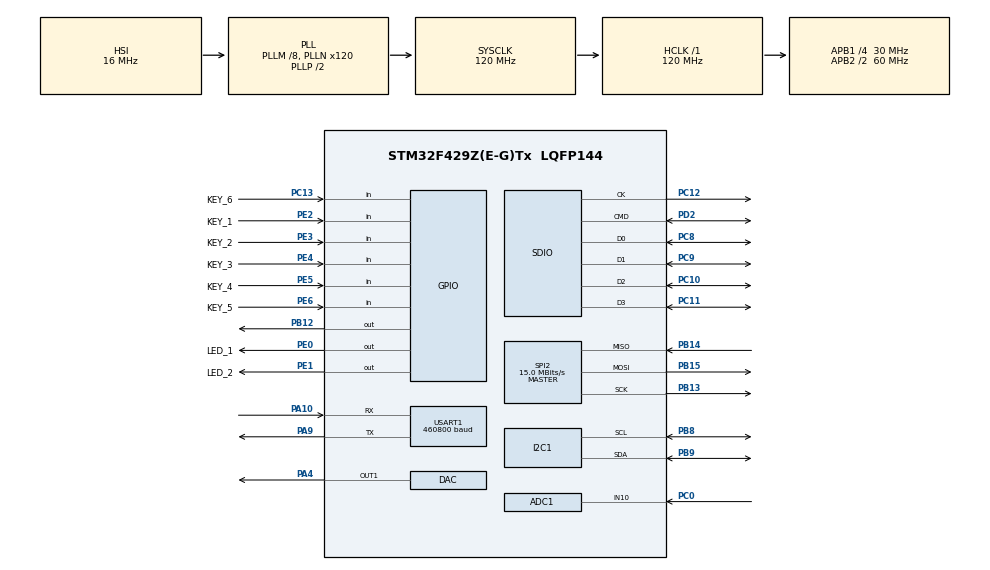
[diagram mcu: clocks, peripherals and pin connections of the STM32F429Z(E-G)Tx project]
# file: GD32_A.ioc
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ADC1.Channel-0\#ChannelRegularConversion=ADC_CHANNEL_10
ADC1.Channel-1\#ChannelRegularConversion=ADC_CHANNEL_10
ADC1.ContinuousConvMode=ENABLE
ADC1.DMAContinuousRequests=ENABLE
ADC1.DiscontinuousConvMode=DISABLE
ADC1.ExternalTrigConv=ADC_SOFTWARE_START
ADC1.NbrOfConversion=2
ADC1.NbrOfConversionFlag=1
ADC1.Rank-0\#ChannelRegularConversion=1
ADC1.Rank-1\#ChannelRegularConversion=2
ADC1.SamplingTime-0\#ChannelRegularConversion=ADC_SAMPLETIME_3CYCLES
ADC1.SamplingTime-1\#ChannelRegularConversion=ADC_SAMPLETIME_3CYCLES
ADC1.ScanConvMode=ENABLE
ADC1.master=1
DAC.DAC_Trigger=DAC_TRIGGER_T6_TRGO
Dma.ADC1.1.Direction=DMA_PERIPH_TO_MEMORY
Dma.ADC1.1.FIFOMode=DMA_FIFOMODE_DISABLE
Dma.ADC1.1.Instance=DMA2_Stream0
Dma.ADC1.1.MemDataAlignment=DMA_MDATAALIGN_WORD
Dma.ADC1.1.MemInc=DMA_MINC_ENABLE
Dma.ADC1.1.Mode=DMA_CIRCULAR
Dma.ADC1.1.PeriphDataAlignment=DMA_PDATAALIGN_WORD
Dma.ADC1.1.PeriphInc=DMA_PINC_DISABLE
Dma.ADC1.1.Priority=DMA_PRIORITY_LOW
Dma.DAC1.2.Direction=DMA_MEMORY_TO_PERIPH
Dma.DAC1.2.FIFOMode=DMA_FIFOMODE_DISABLE
Dma.DAC1.2.Instance=DMA1_Stream5
Dma.DAC1.2.MemDataAlignment=DMA_MDATAALIGN_HALFWORD
Dma.DAC1.2.MemInc=DMA_MINC_ENABLE
Dma.DAC1.2.Mode=DMA_CIRCULAR
Dma.DAC1.2.PeriphDataAlignment=DMA_PDATAALIGN_HALFWORD
Dma.DAC1.2.PeriphInc=DMA_PINC_DISABLE
Dma.DAC1.2.Priority=DMA_PRIORITY_LOW
Dma.Request0=USART1_RX
Dma.Request1=ADC1
Dma.Request2=DAC1
Dma.USART1_RX.0.Direction=DMA_PERIPH_TO_MEMORY
Dma.USART1_RX.0.FIFOMode=DMA_FIFOMODE_DISABLE
Dma.USART1_RX.0.Instance=DMA2_Stream2
Dma.USART1_RX.0.MemDataAlignment=DMA_MDATAALIGN_BYTE
Dma.USART1_RX.0.MemInc=DMA_MINC_ENABLE
Dma.USART1_RX.0.Mode=DMA_NORMAL
Dma.USART1_RX.0.PeriphDataAlignment=DMA_PDATAALIGN_BYTE
Dma.USART1_RX.0.PeriphInc=DMA_PINC_DISABLE
Dma.USART1_RX.0.Priority=DMA_PRIORITY_LOW
FATFS._CODE_PAGE=936
FATFS._USE_LFN=2
Mcu.Family=STM32F4
Mcu.Name=STM32F429Z(E-G)Tx
Mcu.Package=LQFP144
NVIC.ADC_IRQn=true\:0\:0\:false\:false\:true\:true\:true\:true
NVIC.DMA1_Stream5_IRQn=true\:0\:0\:false\:false\:true\:false\:true\:true
NVIC.DMA2_Stream0_IRQn=true\:0\:0\:false\:false\:true\:false\:true\:true
NVIC.DMA2_Stream2_IRQn=true\:0\:0\:false\:false\:true\:false\:true\:true
NVIC.I2C1_ER_IRQn=true\:0\:0\:false\:false\:true\:true\:true\:true
NVIC.I2C1_EV_IRQn=true\:0\:0\:false\:false\:true\:true\:true\:true
NVIC.PriorityGroup=NVIC_PRIORITYGROUP_4
NVIC.RTC_WKUP_IRQn=true\:0\:0\:false\:false\:true\:true\:true\:true
NVIC.SDIO_IRQn=true\:0\:0\:false\:false\:true\:true\:true\:true
NVIC.USART1_IRQn=true\:0\:0\:false\:false\:true\:true\:true\:true
PA10.Mode=Asynchronous
PA10.Signal=USART1_RX
PA13.Mode=Serial_Wire
PA13.Signal=SYS_JTMS-SWDIO
PA14.Mode=Serial_Wire
PA14.Signal=SYS_JTCK-SWCLK
PA4.Signal=COMP_DAC1_group
PA9.Mode=Asynchronous
PA9.Signal=USART1_TX
PB12.Signal=GPIO_Output
PB13.Mode=Full_Duplex_Master
PB13.Signal=SPI2_SCK
PB14.Mode=Full_Duplex_Master
PB14.Signal=SPI2_MISO
PB15.Mode=Full_Duplex_Master
PB15.Signal=SPI2_MOSI
PB8.Mode=I2C
PB8.Signal=I2C1_SCL
PB9.Mode=I2C
PB9.Signal=I2C1_SDA
PC0.Signal=ADCx_IN10
PC10.GPIO_PuPd=GPIO_PULLUP
PC10.Mode=SD_4_bits_Wide_bus
PC10.Signal=SDIO_D2
PC11.GPIO_PuPd=GPIO_PULLUP
PC11.Mode=SD_4_bits_Wide_bus
PC11.Signal=SDIO_D3
PC12.Mode=SD_4_bits_Wide_bus
PC12.Signal=SDIO_CK
PC13.GPIO_Label=KEY_6
PC13.GPIO_Mode=GPIO_MODE_INPUT
PC13.GPIO_PuPd=GPIO_PULLUP
PC13.Signal=GPIO_Input
PC14/OSC32_IN.Mode=LSE-External-Oscillator
PC14/OSC32_IN.Signal=RCC_OSC32_IN
PC15/OSC32_OUT.Mode=LSE-External-Oscillator
PC15/OSC32_OUT.Signal=RCC_OSC32_OUT
PC8.GPIO_PuPd=GPIO_PULLUP
PC8.Mode=SD_4_bits_Wide_bus
PC8.Signal=SDIO_D0
PC9.GPIO_PuPd=GPIO_PULLUP
PC9.Mode=SD_4_bits_Wide_bus
PC9.Signal=SDIO_D1
PD2.GPIO_PuPd=GPIO_PULLUP
PD2.Mode=SD_4_bits_Wide_bus
PD2.Signal=SDIO_CMD
PE0.GPIO_Label=LED_1
PE0.GPIO_PuPd=GPIO_PULLDOWN
PE0.Signal=GPIO_Output
PE1.GPIO_Label=LED_2
PE1.GPIO_PuPd=GPIO_PULLDOWN
PE1.Signal=GPIO_Output
PE2.GPIO_Label=KEY_1
PE2.GPIO_Mode=GPIO_MODE_INPUT
PE2.GPIO_PuPd=GPIO_PULLUP
PE2.Signal=GPIO_Input
PE3.GPIO_Label=KEY_2
PE3.GPIO_Mode=GPIO_MODE_INPUT
PE3.GPIO_PuPd=GPIO_PULLUP
PE3.Signal=GPIO_Input
PE4.GPIO_Label=KEY_3
PE4.GPIO_Mode=GPIO_MODE_INPUT
PE4.GPIO_PuPd=GPIO_PULLUP
PE4.Signal=GPIO_Input
PE5.GPIO_Label=KEY_4
PE5.GPIO_Mode=GPIO_MODE_INPUT
PE5.GPIO_PuPd=GPIO_PULLUP
PE5.Signal=GPIO_Input
PE6.GPIO_Label=KEY_5
PE6.GPIO_Mode=GPIO_MODE_INPUT
PE6.GPIO_PuPd=GPIO_PULLUP
PE6.Signal=GPIO_Input
PH0/OSC_IN.Mode=HSE-External-Oscillator
PH0/OSC_IN.Signal=RCC_OSC_IN
PH1/OSC_OUT.Mode=HSE-External-Oscillator
PH1/OSC_OUT.Signal=RCC_OSC_OUT
ProjectManager.HeapSize=0x1000
ProjectManager.StackSize=0x1000
ProjectManager.TargetToolchain=MDK-ARM V5.32
RCC.48MHZClocksFreq_Value=48000000
RCC.AHBFreq_Value=120000000
RCC.APB1CLKDivider=RCC_HCLK_DIV4
RCC.APB1Freq_Value=30000000
RCC.APB1TimFreq_Value=60000000
RCC.APB2CLKDivider=RCC_HCLK_DIV2
RCC.APB2Freq_Value=60000000
RCC.APB2TimFreq_Value=120000000
RCC.CortexFreq_Value=120000000
RCC.HCLKFreq_Value=120000000
RCC.HSE_VALUE=25000000
RCC.HSI_VALUE=16000000
RCC.PLLM=8
RCC.PLLN=120
RCC.PLLQ=5
RCC.RCC_RTC_Clock_Source=RCC_RTCCLKSOURCE_LSE
RCC.RCC_RTC_Clock_SourceVirtual=RCC_RTCCLKSOURCE_LSE
RCC.SYSCLKFreq_VALUE=120000000
RCC.SYSCLKSource=RCC_SYSCLKSOURCE_PLLCLK
RCC.VCOOutputFreq_Value=240000000
SDIO.ClockDiv=6
SH.ADCx_IN10.0=ADC1_IN10,IN10
SH.COMP_DAC1_group.0=DAC_OUT1,DAC_OUT1
SPI2.CalculateBaudRate=15.0 MBits/s
SPI2.Direction=SPI_DIRECTION_2LINES
SPI2.Mode=SPI_MODE_MASTER
SPI2.VirtualType=VM_MASTER
TIM3.AutoReloadPreload=TIM_AUTORELOAD_PRELOAD_ENABLE
TIM3.Period=100-1
TIM3.Prescaler=180-1
TIM3.TIM_MasterOutputTrigger=TIM_TRGO_UPDATE
TIM6.Prescaler=180-1
USART1.BaudRate=460800
USART1.VirtualMode=VM_ASYNC
VP_FATFS_VS_SDIO.Mode=SDIO
VP_RTC_VS_RTC_Activate.Mode=RTC_Enabled
VP_RTC_VS_RTC_WakeUp_intern.Mode=WakeUp
VP_TIM3_VS_ClockSourceINT.Mode=Internal
VP_TIM6_VS_ClockSourceINT.Mode=Enable_Timer
board=custom

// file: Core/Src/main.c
/* USER CODE BEGIN Header */
/**
  ******************************************************************************
  * @file           : main.c
  * @brief          : Main program body
  ******************************************************************************
  * @attention
  *
  * Copyright (c) 2025 STMicroelectronics.
  * All rights reserved.
  *
  * This software is licensed under terms that can be found in the LICENSE file
  * in the root directory of this software component.
  * If no LICENSE file comes with this software, it is provided AS-IS.
  *
  ******************************************************************************
  */
/* USER CODE END Header */
#include "main.h"
#include "adc.h"
#include "dac.h"
#include "dma.h"
#include "fatfs.h"
#include "i2c.h"
#include "rtc.h"
#include "sdio.h"
#include "spi.h"
#include "tim.h"
#include "usart.h"
#include "gpio.h"

/* USER CODE BEGIN Includes */
#include "mydefine.h"
#include "gd25qxx.h"
#include "data_storage_app.h"

/* USER CODE END Includes */

/* USER CODE BEGIN PV */
FRESULT res;    /* FatFs function common result code */
/* USER CODE END PV */

void SystemClock_Config(void);

int main(void)
{

  /* MCU Configuration--------------------------------------------------------*/

  /* Reset of all peripherals, Initializes the Flash interface and the Systick. */
  HAL_Init();

  /* Configure the system clock */
  SystemClock_Config();

  /* Initialize all configured peripherals */
  MX_GPIO_Init();
  MX_DMA_Init();
  MX_USART1_UART_Init();
  MX_ADC1_Init();
  MX_DAC_Init();
  MX_TIM3_Init();
  MX_TIM6_Init();
  MX_SPI2_Init();
  MX_I2C1_Init();
  MX_SDIO_SD_Init();
  MX_FATFS_Init();
  MX_RTC_Init();
  /* USER CODE BEGIN 2 */
  spi_flash_init();    // Initialize Flash CS pin (must be called before any Flash operations!)

  uart_init();         // 打印系统初始化信息
  adc_dma_init();
  uart_dma_rx_init();  // 启动 UART DMA 接收
  scheduler_init();

  // 数据存储模块初始化
  data_storage_init();
  /* USER CODE END 2 */

  /* Infinite loop */
  while (1)
  {

    /* USER CODE BEGIN 3 */
    scheduler_run();
  }
  /* USER CODE END 3 */
}

void SystemClock_Config(void)
{
  RCC_OscInitTypeDef RCC_OscInitStruct = {0};
  RCC_ClkInitTypeDef RCC_ClkInitStruct = {0};

  /** Configure the main internal regulator output voltage
  */
  __HAL_RCC_PWR_CLK_ENABLE();
  __HAL_PWR_VOLTAGESCALING_CONFIG(PWR_REGULATOR_VOLTAGE_SCALE3);

  /** Initializes the RCC Oscillators according to the specified parameters
  * in the RCC_OscInitTypeDef structure.
  */
  RCC_OscInitStruct.OscillatorType = RCC_OSCILLATORTYPE_HSI|RCC_OSCILLATORTYPE_LSE;
  RCC_OscInitStruct.LSEState = RCC_LSE_ON;
  RCC_OscInitStruct.HSIState = RCC_HSI_ON;
  RCC_OscInitStruct.HSICalibrationValue = RCC_HSICALIBRATION_DEFAULT;
  RCC_OscInitStruct.PLL.PLLState = RCC_PLL_ON;
  RCC_OscInitStruct.PLL.PLLSource = RCC_PLLSOURCE_HSI;
  RCC_OscInitStruct.PLL.PLLM = 8;
  RCC_OscInitStruct.PLL.PLLN = 120;
  RCC_OscInitStruct.PLL.PLLP = RCC_PLLP_DIV2;
  RCC_OscInitStruct.PLL.PLLQ = 5;
  if (HAL_RCC_OscConfig(&RCC_OscInitStruct) != HAL_OK)
  {
    Error_Handler();
  }

  /** Initializes the CPU, AHB and APB buses clocks
  */
  RCC_ClkInitStruct.ClockType = RCC_CLOCKTYPE_HCLK|RCC_CLOCKTYPE_SYSCLK
                              |RCC_CLOCKTYPE_PCLK1|RCC_CLOCKTYPE_PCLK2;
  RCC_ClkInitStruct.SYSCLKSource = RCC_SYSCLKSOURCE_PLLCLK;
  RCC_ClkInitStruct.AHBCLKDivider = RCC_SYSCLK_DIV1;
  RCC_ClkInitStruct.APB1CLKDivider = RCC_HCLK_DIV4;
  RCC_ClkInitStruct.APB2CLKDivider = RCC_HCLK_DIV2;

  if (HAL_RCC_ClockConfig(&RCC_ClkInitStruct, FLASH_LATENCY_3) != HAL_OK)
  {
    Error_Handler();
  }
}

void Error_Handler(void)
{
  __disable_irq();
  while (1)
  {
  }
}
